BO_ 96 CAR_OVERALL_SIGNALS2: 64 XXX
 SG_ CRC1 : 7|8@0+ (1,0) [0|255] "" XXX
 SG_ ACCELARATION : 8|5@0+ (1,0) [0|31] "" XXX
 SG_ COUNTER1 : 59|4@0+ (1,0) [0|15] "" XXX
 SG_ CRC2 : 71|8@0+ (1,0) [0|255] "" XXX
 SG_ BRAKE_SIGNAL : 86|1@0+ (1,0) [0|1] "" XXX

BO_ 147 IMPRECISE_SPEED_INFORMATION: 8 XXX
 SG_ IMPRECISE_SPEED : 15|8@0+ (3.5,0) [0|255] "kph" XXX
 SG_ COUNTER : 59|4@0+ (1,0) [0|15] "" XXX

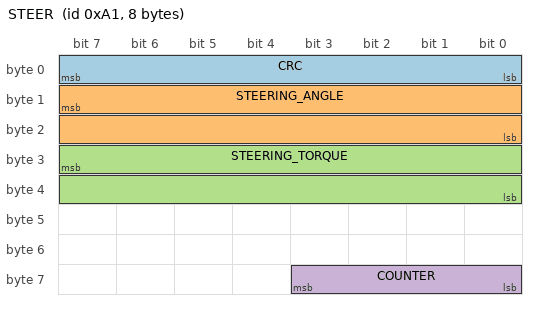
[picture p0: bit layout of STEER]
BO_ 161 STEER: 8 XXX
 SG_ CRC : 7|8@0+ (1,0) [0|255] "" XXX
 SG_ STEERING_ANGLE : 15|16@0+ (0.05,0) [0|65535] "degs" XXX
 SG_ STEERING_TORQUE : 31|16@0+ (1,0) [0|65535] "??" XXX
 SG_ COUNTER : 59|4@0+ (1,0) [0|255] "" XXX

BO_ 259 SPEED: 64 XXX
 SG_ CRC0 : 71|8@0+ (1,0) [0|255] "" XXX
 SG_ COUNTER : 123|4@0+ (1,0) [0|15] "" XXX
 SG_ CRC : 199|8@0+ (1,0) [0|255] "" XXX
 SG_ GAS_POSITION : 231|8@0+ (1,0) [0|255] "" XXX
 SG_ SPEED : 239|8@0+ (1,0) [0|255] "Khp" XXX
 SG_ COUNTER1 : 251|4@0+ (1,0) [0|15] "" XXX
 SG_ COUNTER3 : 315|4@0+ (1,0) [0|15] "" XXX
 SG_ CRC3 : 327|8@0+ (1,0) [0|255] "" XXX

BO_ 288 BRAKE: 64 XXX
 SG_ CRC : 7|8@0+ (1,0) [0|255] "" XXX
 SG_ NEW_SIGNAL_1 : 19|3@0+ (1,0) [0|7] "" XXX
 SG_ BRAKE_PRESSURE : 39|8@0+ (1,-27) [0|255] "" XXX
 SG_ COUNTER : 59|4@0+ (1,0) [0|15] "" XXX

BO_ 303 CAR_OVERALL_SIGNALS: 64 XXX
 SG_ CRC : 71|9@0+ (1,0) [0|511] "" XXX
 SG_ DRIVE_MODE_SIGNAL : 73|1@0+ (1,0) [0|1] "" XXX
 SG_ NEW_SIGNAL_1 : 103|8@0+ (1,0) [0|255] "" XXX
 SG_ COUNTER1 : 123|4@0+ (1,0) [0|15] "" XXX
 SG_ CRC2 : 135|8@0+ (1,0) [0|255] "" XXX
 SG_ DRIVER_MODE_SIGNAL2 : 161|1@0+ (1,0) [0|1] "" XXX
 SG_ DRIVE_MODE : 166|2@0+ (1,0) [0|1] "" XXX
 SG_ COUNTER2 : 187|4@0+ (1,0) [0|15] "" XXX

BO_ 412 LIGHTS: 16 XXX
 SG_ BRAKE_LIGHTS : 24|3@0+ (1,0) [0|7] "" XXX
 SG_ RIGHT_TURN_SIGNAL : 30|1@0+ (1,0) [0|1] "ON/OFF ACCORDINGLY LIGHT" XXX
 SG_ LEFT_TURN_SIGNAL : 31|1@0+ (1,0) [0|1] "ON/OFF ACCORDINGLY LIGHT" XXX

BO_ 649 DRIVE_MODE: 64 XXX
 SG_ DRIVE_MODE_ENABLED : 382|1@0+ (1,0) [0|1] "" XXX
 SG_ DRIVE_MODE_DISABLED : 383|1@0+ (1,0) [0|1] "" XXA

BO_ 714 BUTTONS: 8 XXX
 SG_ LOCK_DOORS_BUTTON : 16|1@0+ (1,0) [0|1] "" XXX

BO_ 837 DOOR_LOCK_STATES: 16 XXX
 SG_ DOOR_LOCK_STATE : 13|1@0+ (1,0) [0|1] "" XXX
 SG_ DOOR_LOCK_STATE2 : 34|1@0+ (1,0) [0|1] "" XXX

BO_ 849 SEATBELT: 16 XXX
 SG_ CRC : 7|8@0+ (1,0) [0|255] "" XXX
 SG_ SEAT_BELT_DRIVER_STATE : 19|1@0+ (1,0) [0|1] "" XXX
 SG_ SEAT_BELT_DRIVER_STATE2 : 33|1@0+ (1,0) [0|1] "" XXX
 SG_ COUNTER : 59|4@0+ (1,0) [0|15] "" XXX

CM_ SG_ 96 BRAKE_SIGNAL "1 = BRAKE PRESSED";
CM_ SG_ 147 IMPRECISE_SPEED "lower precision, reverse is positive as well";
CM_ SG_ 161 STEERING_ANGLE "0 CENTER, NO LEFT / RIGHT SIGNAL";
CM_ SG_ 161 STEERING_TORQUE "Peak identified 3680, 0 = stopped";
CM_ SG_ 259 GAS_POSITION "17 = 0, 253 = FULL, SOMETIMES 4";
CM_ SG_ 259 SPEED "PRECISE, KPH, DASHBOARD SPEED, BIT LOWER THAN GPS SPEED";
CM_ SG_ 288 BRAKE_PRESSURE "ODD BRAKE PRESSURE, NEGATIVE/OFFSET";
CM_ SG_ 303 DRIVE_MODE_SIGNAL "D/R = 0 | N/P = 1";
CM_ SG_ 303 DRIVER_MODE_SIGNAL2 "D/R = 1 | N/P=0";
CM_ SG_ 303 DRIVE_MODE "0 = P | 1 = D | 2 = N | 3 = R (GOOD SIGNAL)";
CM_ SG_ 412 BRAKE_LIGHTS "POSSIBLE 3 DIFFERENT LIGHTS";
CM_ SG_ 412 LEFT_TURN_SIGNAL "ON/OFF ACCORDINGLY LIGHT";
CM_ BO_ 649 "FRONT";
CM_ SG_ 649 DRIVE_MODE_ENABLED "DRIVE = 1 | OTHER MODES = 0";
CM_ SG_ 649 DRIVE_MODE_DISABLED "D = 0 | OTHER MODES = 0";
CM_ SG_ 714 LOCK_DOORS_BUTTON "1 = PRESSED";
CM_ SG_ 837 DOOR_LOCK_STATE "0 = LOCKED / 1 = UNLOCKED";
CM_ SG_ 837 DOOR_LOCK_STATE2 "0 = LOCKED / 1 = UNLOCKED";
CM_ SG_ 849 SEAT_BELT_DRIVER_STATE "0 = Fastened / 1 = Released";
CM_ SG_ 849 SEAT_BELT_DRIVER_STATE2 "0 = Fastened / 1 = Released";
